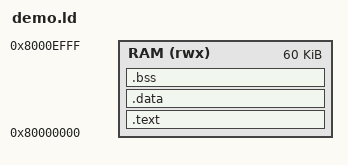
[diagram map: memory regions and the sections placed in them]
OUTPUT_ARCH(riscv)
ENTRY(_start)
MEMORY { RAM (rwx) : ORIGIN = 0x80000000, LENGTH = 61440 }
SECTIONS {
    .text : { KEEP(*(.text.start)) *(.text*) *(.rodata*) } > RAM
    .data : { *(.data*) *(.sdata*) } > RAM
    .bss (NOLOAD) : {
        . = ALIGN(4); _bss_start = .;
        *(.bss*) *(.sbss*) *(COMMON)
        . = ALIGN(4); _bss_end = .;
    } > RAM
    _stack_top = 0x80010000;
    ASSERT(_bss_end <= 0x8000f000, "Application overlaps stack")
    /DISCARD/ : { *(.comment) *(.eh_frame*) }
}
